VERSION ""

NS_ :

BS_:

BU_: VCU SES

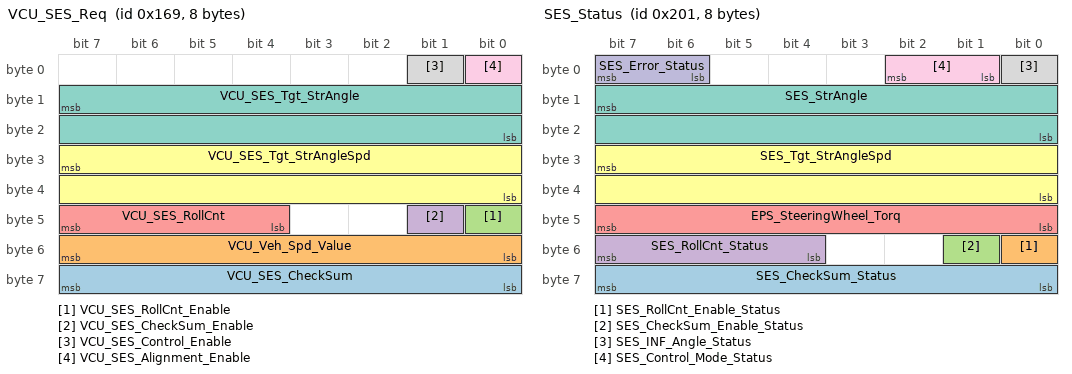
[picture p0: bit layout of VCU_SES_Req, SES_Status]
BO_ 361 VCU_SES_Req: 8 VCU
 SG_ VCU_SES_CheckSum : 63|8@0+ (1,0) [0|255] ""  SES
 SG_ VCU_Veh_Spd_Value : 55|8@0+ (1,0) [0|255] ""  SES
 SG_ VCU_SES_RollCnt_Enable : 40|1@0+ (1,0) [0|1] ""  SES
 SG_ VCU_SES_CheckSum_Enable : 41|1@0+ (1,0) [0|1] ""  SES
 SG_ VCU_SES_RollCnt : 47|4@0+ (1,0) [0|15] ""  SES
 SG_ VCU_SES_Tgt_StrAngleSpd : 31|16@0+ (1,0) [125|525] "°/s"  SES
 SG_ VCU_SES_Tgt_StrAngle : 15|16@0- (0.1,-3000) [-700|700] "°"  SES
 SG_ VCU_SES_Control_Enable : 1|1@0+ (1,0) [0|2] ""  SES
 SG_ VCU_SES_Alignment_Enable : 0|1@0+ (1,0) [0|1] ""  SES

BO_ 513 SES_Status: 8 SES
 SG_ SES_CheckSum_Status : 63|8@0+ (1,0) [0|255] ""  VCU
 SG_ SES_RollCnt_Enable_Status : 48|1@0+ (1,0) [0|1] ""  SES
 SG_ SES_CheckSum_Enable_Status : 49|1@0+ (1,0) [0|1] ""  VCU
 SG_ SES_RollCnt_Status : 55|4@0+ (1,0) [0|15] ""  VCU
 SG_ EPS_SteeringWheel_Torq : 47|8@0+ (1,0) [0|255] "Nm"  VCU
 SG_ SES_Tgt_StrAngleSpd : 31|16@0- (0.5,0) [0|1480] "°/s"  VCU
 SG_ SES_StrAngle : 15|16@0+ (0.1,-3000) [-700|700] "°"  VCU
 SG_ SES_INF_Angle_Status : 0|1@0+ (1,0) [0|1] ""  VCU
 SG_ SES_Control_Mode_Status : 2|2@0+ (1,0) [0|3] ""  VCU
 SG_ SES_Error_Status : 7|2@0+ (1,0) [0|3] ""  VCU

BO_ 514 SES_ErrInfo: 8 SES
 SG_ SES_Veh_Spd_Value : 63|8@0+ (1,0) [0|1] ""  VCU
 SG_ SES_EPROM_Err : 24|1@0+ (1,0) [0|1] ""  VCU
 SG_ SES_StrMtr_Idling_Err : 23|1@0+ (1,0) [0|1] ""  VCU
 SG_ SentAngle_Err : 22|1@0+ (1,0) [0|1] ""  VCU
 SG_ SES_TorqSensor_T2_AF_Err : 21|1@0+ (1,0) [0|1] ""  VCU
 SG_ SES_TorqSensor_T1_AF_Err : 20|1@0+ (1,0) [0|1] ""  VCU
 SG_ SES_TorqSensor_T2_O_C_Err : 19|1@0+ (1,0) [0|1] ""  VCU
 SG_ SES_TorqSensor_T1_O_C_Err : 18|1@0+ (1,0) [0|1] ""  VCU
 SG_ SES_Sensor_sCL__Err : 17|1@0+ (1,0) [0|1] ""  VCU
 SG_ SES_MtrCurt_Err : 16|1@0+ (1,0) [0|1] ""  VCU
 SG_ SES_StrMtr_Stall_Err : 15|1@0+ (1,0) [0|1] ""  VCU
 SG_ SES_OverAngle_Err : 14|1@0+ (1,0) [0|1] ""  VCU
 SG_ SES_Alignment_Err : 13|1@0+ (1,0) [0|1] ""  VCU
 SG_ SES_SensorPow_Err : 12|1@0+ (1,0) [0|1] ""  VCU
 SG_ SES_AngleSensor_S_AF_Err : 11|1@0+ (1,0) [0|1] ""  VCU
 SG_ SES_AngleSensor_S_O_C_Err : 10|1@0+ (1,0) [0|1] ""  VCU
 SG_ SES_AngleSensor_P_AF_Err : 9|1@0+ (1,0) [0|1] ""  VCU
 SG_ SES_AngleSensor_P_O_C_Err : 8|1@0+ (1,0) [0|1] ""  VCU
 SG_ SES_TempSensor_Err : 7|1@0+ (1,0) [0|1] ""  VCU
 SG_ SES_Domain_drive_T_Err : 6|1@0+ (1,0) [0|1] ""  VCU
 SG_ SES_Domain_drive_V_Err : 5|1@0+ (1,0) [0|1] ""  VCU
 SG_ SES_Domain_drive_SC_Err : 4|1@0+ (1,0) [0|1] ""  VCU
 SG_ SES_ECUTemp_Err : 3|1@0+ (1,0) [0|1] ""  VCU
 SG_ SES_CanCom_Err : 2|1@0+ (1,0) [0|1] ""  VCU
 SG_ SES_ECUOverVolt_Err : 1|1@0+ (1,0) [0|1] ""  VCU
 SG_ SES_ECUUnderVolt_Err : 0|1@0+ (1,0) [0|1] ""  VCU

BO_ 515 SES_Version: 8 SES
 SG_ SES_HW_Version : 15|8@0+ (0.1,0) [0|25.5] ""  VCU
 SG_ SES_SW_Version : 7|8@0+ (0.01,0) [0|255] ""  VCU

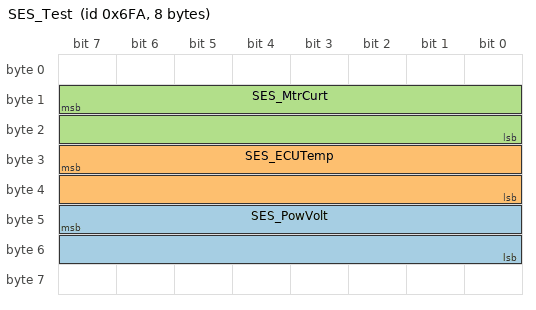
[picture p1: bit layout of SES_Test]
BO_ 1786 SES_Test: 8 SES
 SG_ SES_PowVolt : 47|16@0+ (0.00390625,0) [0|18] ""  VCU
 SG_ SES_ECUTemp : 31|16@0+ (0.5,0) [0|255] ""  VCU
 SG_ SES_MtrCurt : 15|16@0- (0.0078125,0) [0|60] ""  VCU

BO_TX_BU_ 513 : VCU,SES;

VAL_ 361 VCU_SES_Control_Enable 0 "Disabled-Default Assist mode/0x0" 1 "Rising Edge Enable-Angle Control Mode" ;
VAL_ 361 VCU_SES_Alignment_Enable 0 "/" 1 "centering;" ;
VAL_ 513 SES_CheckSum_Enable_Status 0 "Invalid0x1: Valid" ;
VAL_ 513 SES_INF_Angle_Status 0 "Center Finding0x1: Found" ;
VAL_ 513 SES_Control_Mode_Status 0 "Manual Mode0x1: Automatic Mode" ;
VAL_ 513 SES_Error_Status 0 "Normal0x1: Level 1 Warning..." ;
VAL_ 514 SES_EPROM_Err 0 "False0x1: True" ;
VAL_ 514 SES_StrMtr_Idling_Err 0 "False0x1: True" ;
VAL_ 514 SentAngle_Err 0 "False0x1: True" ;
VAL_ 514 SES_TorqSensor_T2_AF_Err 0 "False0x1: True" ;
VAL_ 514 SES_TorqSensor_T1_AF_Err 0 "False0x1: True" ;
VAL_ 514 SES_TorqSensor_T2_O_C_Err 0 "False0x1: True" ;
VAL_ 514 SES_TorqSensor_T1_O_C_Err 0 "False0x1: True" ;
VAL_ 514 SES_Sensor_sCL__Err 0 "False0x1: True" ;
VAL_ 514 SES_MtrCurt_Err 0 "False0x1: True" ;
VAL_ 514 SES_StrMtr_Stall_Err 0 "False0x1: True" ;
VAL_ 514 SES_OverAngle_Err 0 "False0x1: True" ;
VAL_ 514 SES_Alignment_Err 0 "False0x1: True" ;
VAL_ 514 SES_SensorPow_Err 0 "False0x1: True" ;
VAL_ 514 SES_AngleSensor_S_AF_Err 0 "False0x1: True" ;
VAL_ 514 SES_AngleSensor_S_O_C_Err 0 "False0x1: True" ;
VAL_ 514 SES_AngleSensor_P_AF_Err 0 "False0x1: True" ;
VAL_ 514 SES_AngleSensor_P_O_C_Err 0 "False0x1: True" ;
VAL_ 514 SES_TempSensor_Err 0 "False0x1: True" ;
VAL_ 514 SES_Domain_drive_T_Err 0 "False0x1: True" ;
VAL_ 514 SES_Domain_drive_V_Err 0 "False0x1: True" ;
VAL_ 514 SES_Domain_drive_SC_Err 0 "False0x1: True" ;
VAL_ 514 SES_ECUTemp_Err 0 "False0x1: True" ;
VAL_ 514 SES_CanCom_Err 0 "False0x1: True" ;
VAL_ 514 SES_ECUOverVolt_Err 0 "False0x1: True" ;
VAL_ 514 SES_ECUUnderVolt_Err 0 "False0x1: True" ;
